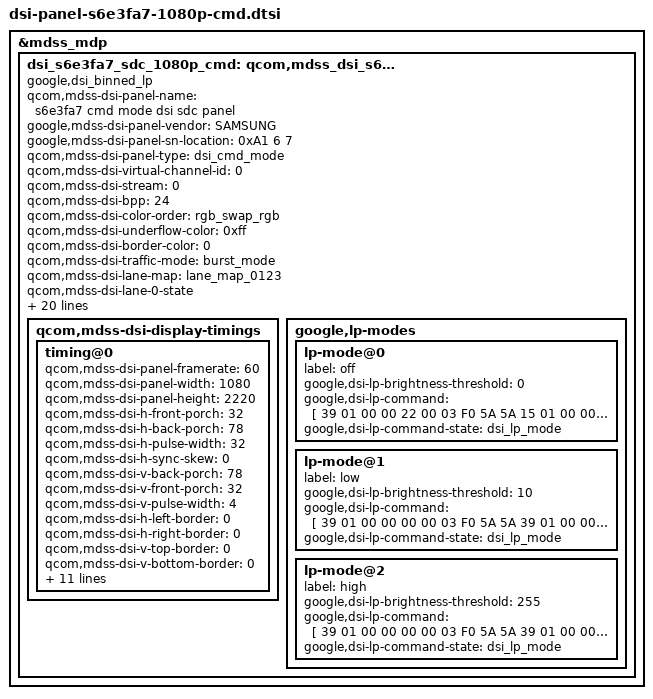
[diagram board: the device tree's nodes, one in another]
/* Copyright (c) 2018, The Linux Foundation. All rights reserved.
 *
 * This program is free software; you can redistribute it and/or modify
 * it under the terms of the GNU General Public License version 2 and
 * only version 2 as published by the Free Software Foundation.
 *
 * This program is distributed in the hope that it will be useful,
 * but WITHOUT ANY WARRANTY; without even the implied warranty of
 * MERCHANTABILITY or FITNESS FOR A PARTICULAR PURPOSE.  See the
 * GNU General Public License for more details.
 */

&mdss_mdp {
	dsi_s6e3fa7_sdc_1080p_cmd: qcom,mdss_dsi_s6e3fa7_sdc_1080p_cmd {
		compatible = "google,dsi_binned_lp";

		qcom,mdss-dsi-panel-name = "s6e3fa7 cmd mode dsi sdc panel";
		google,mdss-dsi-panel-vendor = "SAMSUNG";
		google,mdss-dsi-panel-sn-location = <0xA1 6 7>;
		qcom,mdss-dsi-panel-type = "dsi_cmd_mode";
		qcom,mdss-dsi-virtual-channel-id = <0>;
		qcom,mdss-dsi-stream = <0>;
		qcom,mdss-dsi-bpp = <24>;
		qcom,mdss-dsi-color-order = "rgb_swap_rgb";
		qcom,mdss-dsi-underflow-color = <0xff>;
		qcom,mdss-dsi-border-color = <0>;
		qcom,mdss-dsi-traffic-mode = "burst_mode";
		qcom,mdss-dsi-lane-map = "lane_map_0123";
		qcom,mdss-dsi-lane-0-state;
		qcom,mdss-dsi-lane-1-state;
		qcom,mdss-dsi-lane-2-state;
		qcom,mdss-dsi-lane-3-state;
		qcom,mdss-dsi-reset-sequence = <0 1>, <1 10>;
		qcom,mdss-dsi-dma-trigger = "trigger_sw";
		qcom,mdss-dsi-mdp-trigger = "none";
		qcom,mdss-dsi-te-pin-select = <1>;
		qcom,mdss-dsi-wr-mem-start = <0x2c>;
		qcom,mdss-dsi-wr-mem-continue = <0x3c>;
		qcom,mdss-dsi-te-dcs-command = <1>;
		qcom,mdss-dsi-te-check-enable;
		qcom,mdss-dsi-te-using-te-pin;
		qcom,mdss-dsi-lp11-init;
		qcom,mdss-dsi-tx-eot-append;

		qcom,mdss-pan-physical-width-dimension = <62>;
		qcom,mdss-pan-physical-height-dimension = <127>;

		qcom,mdss-dsi-bl-pmic-control-type = "bl_ctrl_dcs";
		qcom,mdss-dsi-bl-min-level = <3>;
		qcom,mdss-dsi-bl-max-level = <1023>; /* 10 bit */

		qcom,mdss-dsi-display-timings {
			timing@0 {
				qcom,mdss-dsi-panel-framerate = <60>;
				qcom,mdss-dsi-panel-width = <1080>;
				qcom,mdss-dsi-panel-height = <2220>;
				qcom,mdss-dsi-h-front-porch = <32>;
				qcom,mdss-dsi-h-back-porch = <78>;
				qcom,mdss-dsi-h-pulse-width = <32>;
				qcom,mdss-dsi-h-sync-skew = <0>;
				qcom,mdss-dsi-v-back-porch = <78>;
				qcom,mdss-dsi-v-front-porch = <32>;
				qcom,mdss-dsi-v-pulse-width = <4>;
				qcom,mdss-dsi-h-left-border = <0>;
				qcom,mdss-dsi-h-right-border = <0>;
				qcom,mdss-dsi-v-top-border = <0>;
				qcom,mdss-dsi-v-bottom-border = <0>;
				qcom,mdss-dsi-on-command = [
					05 01 00 00 14 00 01 11
					15 01 00 00 00 00 02 35 00
					/* TBD ERR_FG on */
					/* TBD AVC on
					 *15 01 00 00 00 00 03 F0 5A 5A
					 *39 01 00 00 00 00 0F F4 BB 23 19 3A 9F
					 *	0F 09 C0 00 B4 37 70 79 69
					 *15 01 00 00 00 00 03 F0 A5 A5
					 */
					15 01 00 00 7C 00 02 53 20
					05 01 00 00 00 00 01 29
				];
				qcom,mdss-dsi-off-command = [
					05 01 00 00 00 00 01 28
					05 01 00 00 78 00 01 10
				];
				qcom,mdss-dsi-lp1-command = [
					05 01 00 00 00 00 01 28
					/* HLPM on: 50nit */
					39 01 00 00 00 00 03 F0 5A 5A
					39 01 00 00 00 00 06 BB 15 0C 06 10 F5
					15 01 00 00 00 00 02 53 22
					15 01 00 00 00 00 02 F7 03
					39 01 00 00 11 00 03 F0 A5 A5
				];
				qcom,mdss-dsi-nolp-command = [
					/* HLPM off */
					39 01 00 00 22 00 03 F0 5A 5A
					15 01 00 00 11 00 02 53 20
					39 01 00 00 00 00 03 F0 A5 A5
				];
				qcom,mdss-dsi-on-command-state = "dsi_lp_mode";
				qcom,mdss-dsi-off-command-state = "dsi_lp_mode";
				qcom,mdss-dsi-h-sync-pulse = <0>;
			};
		};

		google,lp-modes {
			lp-mode@0 {
				label = "off";
				google,dsi-lp-brightness-threshold = <0>;
				google,dsi-lp-command = [
					/* HLPM off */
					39 01 00 00 22 00 03 F0 5A 5A
					15 01 00 00 11 00 02 53 20
					39 01 00 00 00 00 03 F0 A5 A5
				];
				google,dsi-lp-command-state = "dsi_lp_mode";
			};

			lp-mode@1 {
				label = "low";
				google,dsi-lp-brightness-threshold = <10>;
				google,dsi-lp-command = [
					/* HLPM on: 10nit */
					39 01 00 00 00 00 03 F0 5A 5A
					39 01 00 00 00 00 06 BB 15 8C 06 10 F5
					15 01 00 00 00 00 02 53 23
					15 01 00 00 00 00 02 F7 03
					39 01 00 00 11 00 03 F0 A5 A5
					05 01 00 00 00 00 01 29
				];
				google,dsi-lp-command-state = "dsi_lp_mode";
			};

			lp-mode@2 {
				label = "high";
				google,dsi-lp-brightness-threshold = <255>;
				google,dsi-lp-command = [
					/* HLPM on: 50nit */
					39 01 00 00 00 00 03 F0 5A 5A
					39 01 00 00 00 00 06 BB 15 0C 06 10 F5
					15 01 00 00 00 00 02 53 22
					15 01 00 00 00 00 02 F7 03
					39 01 00 00 11 00 03 F0 A5 A5
					05 01 00 00 00 00 01 29
				];
				google,dsi-lp-command-state = "dsi_lp_mode";
			};
		};
	};
};
